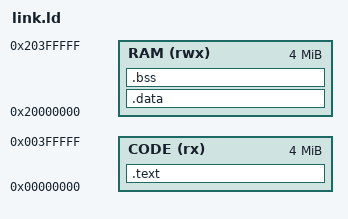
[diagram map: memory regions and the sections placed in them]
/* the mps2-an386 board as qemu emulates it: 4 MB of memory at 0 for code
   and constants (the weights), 4 MB at 0x20000000 for data, the arena and
   the stack. qemu loads every section of the ELF where it is linked */
MEMORY
{
    CODE (rx)  : ORIGIN = 0x00000000, LENGTH = 4M
    RAM  (rwx) : ORIGIN = 0x20000000, LENGTH = 4M
}

ENTRY(reset_handler)

SECTIONS
{
    .text : {
        KEEP(*(.vectors))
        *(.text*)
        *(.rodata*)
    } > CODE

    .data : { *(.data*) } > RAM

    .bss (NOLOAD) : {
        . = ALIGN(4);
        __bss_start__ = .;
        *(.bss*)
        *(COMMON)
        . = ALIGN(4);
        __bss_end__ = .;
    } > RAM

    __stack_top__ = ORIGIN(RAM) + LENGTH(RAM);
}
